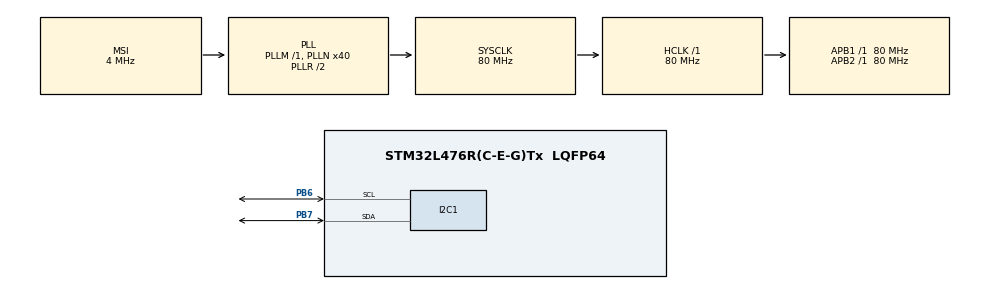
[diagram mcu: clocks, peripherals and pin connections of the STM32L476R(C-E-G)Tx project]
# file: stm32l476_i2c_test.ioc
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I2C1.AddressingMode=I2C_ADDRESSINGMODE_7BIT
I2C1.NoStretchMode=I2C_NOSTRETCH_DISABLE
I2C1.OwnAddress=0x0C
I2C1.Speed=1
I2C1.Timing=0x00000000
Mcu.Family=STM32L4
Mcu.Name=STM32L476R(C-E-G)Tx
Mcu.Package=LQFP64
NVIC.I2C1_ER_IRQn=true\:0\:0\:false\:false\:true\:true\:true
NVIC.I2C1_EV_IRQn=true\:0\:0\:false\:false\:true\:true\:true
NVIC.PriorityGroup=NVIC_PRIORITYGROUP_4
PB6.Mode=I2C
PB6.Signal=I2C1_SCL
PB7.Mode=I2C
PB7.Signal=I2C1_SDA
ProjectManager.HeapSize=0x200
ProjectManager.StackSize=0x400
ProjectManager.TargetToolchain=STM32CubeIDE
RCC.AHBFreq_Value=80000000
RCC.APB1Freq_Value=80000000
RCC.APB1TimFreq_Value=80000000
RCC.APB2Freq_Value=80000000
RCC.APB2TimFreq_Value=80000000
RCC.CortexFreq_Value=80000000
RCC.HCLKFreq_Value=80000000
RCC.HSE_VALUE=8000000
RCC.HSI_VALUE=16000000
RCC.LSE_VALUE=32768
RCC.MSI_VALUE=4000000
RCC.PLLN=40
RCC.SYSCLKFreq_VALUE=80000000
RCC.SYSCLKSource=RCC_SYSCLKSOURCE_PLLCLK
RCC.VCOOutputFreq_Value=160000000
board=custom

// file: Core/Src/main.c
/* USER CODE BEGIN Header */
/**
  ******************************************************************************
  * @file           : main.c
  * @brief          : Main program body
  ******************************************************************************
  * @attention
  *
  * <h2><center>&copy; Copyright (c) 2020 STMicroelectronics.
  * All rights reserved.</center></h2>
  *
  * This software component is licensed by ST under BSD 3-Clause license,
  * the "License"; You may not use this file except in compliance with the
  * License. You may obtain a copy of the License at:
  *                        opensource.org/licenses/BSD-3-Clause
  *
  ******************************************************************************
  */
/* USER CODE END Header */
#include "main.h"
#include "i2c.h"
#include "gpio.h"

void SystemClock_Config(void);

/* USER CODE BEGIN 0 */
/* Buffer used for transmission */
/* Size of Transmission buffer */
#define TXBUFFERSIZE                      (2)
#define RXBUFFERSIZE                      (3)
uint8_t aSlaveTxBuffer[TXBUFFERSIZE] = {0xA5, 0x5A};
uint8_t aSlaveRxBuffer[RXBUFFERSIZE];
int uSlaveTxCount = 0;
int uSlaveRxCount = 0;
int uSlaveListenCount = 0;
int uI2C1AddrMatchCount = 0;
/* USER CODE END 0 */

int main(void)
{

  /* MCU Configuration--------------------------------------------------------*/

  /* Reset of all peripherals, Initializes the Flash interface and the Systick. */
  HAL_Init();

  /* Configure the system clock */
  SystemClock_Config();

  /* Initialize all configured peripherals */
  MX_GPIO_Init();
  MX_I2C1_Init();
  /* USER CODE BEGIN 2 */
  if(HAL_I2C_EnableListen_IT(&hi2c1) != HAL_OK)
  {
    Error_Handler();
  }
  /* USER CODE END 2 */

  /* Infinite loop */
  while (1)
  {

  }
}

void SystemClock_Config(void)
{
  RCC_OscInitTypeDef RCC_OscInitStruct = {0};
  RCC_ClkInitTypeDef RCC_ClkInitStruct = {0};
  RCC_PeriphCLKInitTypeDef PeriphClkInit = {0};

  /** Initializes the RCC Oscillators according to the specified parameters
  * in the RCC_OscInitTypeDef structure.
  */
  RCC_OscInitStruct.OscillatorType = RCC_OSCILLATORTYPE_MSI;
  RCC_OscInitStruct.MSIState = RCC_MSI_ON;
  RCC_OscInitStruct.MSICalibrationValue = 0;
  RCC_OscInitStruct.MSIClockRange = RCC_MSIRANGE_6;
  RCC_OscInitStruct.PLL.PLLState = RCC_PLL_ON;
  RCC_OscInitStruct.PLL.PLLSource = RCC_PLLSOURCE_MSI;
  RCC_OscInitStruct.PLL.PLLM = 1;
  RCC_OscInitStruct.PLL.PLLN = 40;
  RCC_OscInitStruct.PLL.PLLP = RCC_PLLP_DIV7;
  RCC_OscInitStruct.PLL.PLLQ = RCC_PLLQ_DIV2;
  RCC_OscInitStruct.PLL.PLLR = RCC_PLLR_DIV2;
  if (HAL_RCC_OscConfig(&RCC_OscInitStruct) != HAL_OK)
  {
    Error_Handler();
  }
  /** Initializes the CPU, AHB and APB buses clocks
  */
  RCC_ClkInitStruct.ClockType = RCC_CLOCKTYPE_HCLK|RCC_CLOCKTYPE_SYSCLK
                              |RCC_CLOCKTYPE_PCLK1|RCC_CLOCKTYPE_PCLK2;
  RCC_ClkInitStruct.SYSCLKSource = RCC_SYSCLKSOURCE_PLLCLK;
  RCC_ClkInitStruct.AHBCLKDivider = RCC_SYSCLK_DIV1;
  RCC_ClkInitStruct.APB1CLKDivider = RCC_HCLK_DIV1;
  RCC_ClkInitStruct.APB2CLKDivider = RCC_HCLK_DIV1;

  if (HAL_RCC_ClockConfig(&RCC_ClkInitStruct, FLASH_LATENCY_4) != HAL_OK)
  {
    Error_Handler();
  }
  PeriphClkInit.PeriphClockSelection = RCC_PERIPHCLK_I2C1;
  PeriphClkInit.I2c1ClockSelection = RCC_I2C1CLKSOURCE_PCLK1;
  if (HAL_RCCEx_PeriphCLKConfig(&PeriphClkInit) != HAL_OK)
  {
    Error_Handler();
  }
  /** Configure the main internal regulator output voltage
  */
  if (HAL_PWREx_ControlVoltageScaling(PWR_REGULATOR_VOLTAGE_SCALE1) != HAL_OK)
  {
    Error_Handler();
  }
}

/* USER CODE BEGIN 4 */
void HAL_I2C_AddrCallback(I2C_HandleTypeDef *hi2c, uint8_t TransferDirection, uint16_t AddrMatchCode)
{
  if(hi2c->Instance == I2C1)
  {
    uI2C1AddrMatchCount++;

    if(TransferDirection == I2C_DIRECTION_TRANSMIT) //slave receive mode
    {
      if(HAL_I2C_Slave_Sequential_Receive_IT(&hi2c1, (uint8_t *)aSlaveRxBuffer, RXBUFFERSIZE, I2C_NEXT_FRAME) != HAL_OK)
      {
        Error_Handler();
      }
    }
    else if(TransferDirection == I2C_DIRECTION_RECEIVE) //slave trasfer mode
    {
      switch(aSlaveRxBuffer[0])
      {
        case 0x01:
          if(HAL_I2C_Slave_Sequential_Transmit_IT(&hi2c1, (uint8_t *)aSlaveTxBuffer, TXBUFFERSIZE, I2C_LAST_FRAME) != HAL_OK)
          {
            Error_Handler();
          }
          break;

        default:
          break;
      }
    }
  }
}

void HAL_I2C_SlaveTxCpltCallback(I2C_HandleTypeDef *hi2c)
{
  if(hi2c->Instance == I2C1)
  {
    uSlaveTxCount++;
  }
}

void HAL_I2C_SlaveRxCpltCallback(I2C_HandleTypeDef *hi2c)
{
  if(hi2c->Instance == I2C1)
  {
    uSlaveRxCount++;
  }
}

void HAL_I2C_ListenCpltCallback(I2C_HandleTypeDef *hi2c)
{
  if(hi2c->Instance == I2C1)
  {
    uSlaveListenCount++;
    if(HAL_I2C_EnableListen_IT(&hi2c1) != HAL_OK)
    {
      Error_Handler();
    }
  }
}
/* USER CODE END 4 */

void Error_Handler(void)
{
  /* USER CODE BEGIN Error_Handler_Debug */
  /* User can add his own implementation to report the HAL error return state */
  while(1);
  /* USER CODE END Error_Handler_Debug */
}

/************************ (C) COPYRIGHT STMicroelectronics *****END OF FILE****/
